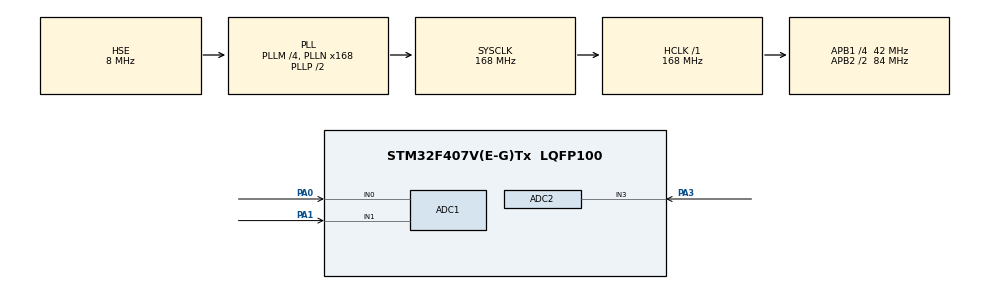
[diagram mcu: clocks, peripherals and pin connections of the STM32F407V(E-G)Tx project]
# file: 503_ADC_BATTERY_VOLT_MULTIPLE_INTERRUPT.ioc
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ADC1.Channel-0\#ChannelRegularConversion=ADC_CHANNEL_VREFINT
ADC1.Channel-3\#ChannelRegularConversion=ADC_CHANNEL_0
ADC1.Channel-4\#ChannelRegularConversion=ADC_CHANNEL_1
ADC1.ContinuousConvMode=ENABLE
ADC1.NbrOfConversion=3
ADC1.NbrOfConversionFlag=1
ADC1.Rank-3\#ChannelRegularConversion=2
ADC1.Rank-4\#ChannelRegularConversion=3
ADC1.SamplingTime-0\#ChannelRegularConversion=ADC_SAMPLETIME_480CYCLES
ADC1.SamplingTime-3\#ChannelRegularConversion=ADC_SAMPLETIME_480CYCLES
ADC1.SamplingTime-4\#ChannelRegularConversion=ADC_SAMPLETIME_480CYCLES
ADC1.master=1
ADC2.Channel-2\#ChannelRegularConversion=ADC_CHANNEL_3
ADC2.ContinuousConvMode=ENABLE
ADC2.NbrOfConversionFlag=1
ADC2.Rank-2\#ChannelRegularConversion=1
ADC2.SamplingTime-2\#ChannelRegularConversion=ADC_SAMPLETIME_480CYCLES
Mcu.Family=STM32F4
Mcu.Name=STM32F407V(E-G)Tx
Mcu.Package=LQFP100
NVIC.ADC_IRQn=true\:0\:0\:false\:false\:true\:true\:true\:true
NVIC.PriorityGroup=NVIC_PRIORITYGROUP_4
PA0-WKUP.Signal=ADCx_IN0
PA1.Signal=ADCx_IN1
PA13.Mode=Serial_Wire
PA13.Signal=SYS_JTMS-SWDIO
PA14.Mode=Serial_Wire
PA14.Signal=SYS_JTCK-SWCLK
PA3.Signal=ADCx_IN3
PH0-OSC_IN.Mode=HSE-External-Oscillator
PH0-OSC_IN.Signal=RCC_OSC_IN
PH1-OSC_OUT.Mode=HSE-External-Oscillator
PH1-OSC_OUT.Signal=RCC_OSC_OUT
ProjectManager.HeapSize=0x200
ProjectManager.StackSize=0x400
ProjectManager.TargetToolchain=STM32CubeIDE
RCC.48MHZClocksFreq_Value=84000000
RCC.AHBFreq_Value=168000000
RCC.APB1CLKDivider=RCC_HCLK_DIV4
RCC.APB1Freq_Value=42000000
RCC.APB1TimFreq_Value=84000000
RCC.APB2CLKDivider=RCC_HCLK_DIV2
RCC.APB2Freq_Value=84000000
RCC.APB2TimFreq_Value=168000000
RCC.CortexFreq_Value=168000000
RCC.HCLKFreq_Value=168000000
RCC.HSE_VALUE=8000000
RCC.HSI_VALUE=16000000
RCC.LSE_VALUE=32768
RCC.PLLM=4
RCC.PLLN=168
RCC.PLLSourceVirtual=RCC_PLLSOURCE_HSE
RCC.SYSCLKFreq_VALUE=168000000
RCC.SYSCLKSource=RCC_SYSCLKSOURCE_PLLCLK
RCC.VCOOutputFreq_Value=336000000
SH.ADCx_IN0.0=ADC1_IN0,IN0
SH.ADCx_IN1.0=ADC1_IN1,IN1
SH.ADCx_IN3.0=ADC2_IN3,IN3
VP_ADC1_Vref_Input.Mode=IN-Vrefint
board=custom

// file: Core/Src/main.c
/* USER CODE BEGIN Header */
/**
  ******************************************************************************
  * @file           : main.c
  * @brief          : Main program body
  ******************************************************************************
  * @attention
  *
  * Copyright (c) 2024 STMicroelectronics.
  * All rights reserved.
  *
  * This software is licensed under terms that can be found in the LICENSE file
  * in the root directory of this software component.
  * If no LICENSE file comes with this software, it is provided AS-IS.
  *
  ******************************************************************************
  */
/* USER CODE END Header */
#include "main.h"

/* USER CODE BEGIN PTD */
#define VREFIN_CAL ((uint16_t*)((uint32_t)0x1FFF7A2A))
uint16_t adc1_value [3];
uint16_t adc2_value;

float Vdda = 0, Vadc1_bat1, Vadc1_bat2, Vadc2_bat1;

int count;

/* USER CODE END PTD */

ADC_HandleTypeDef hadc1;
ADC_HandleTypeDef hadc2;

void SystemClock_Config(void);
static void MX_GPIO_Init(void);
static void MX_ADC1_Init(void);
static void MX_ADC2_Init(void);

/* USER CODE BEGIN 0 */
void HAL_ADC_ConvCpltCallback(ADC_HandleTypeDef *hadc)
{
	if(__HAL_ADC_GET_FLAG(&hadc1, ADC_FLAG_EOC) != RESET )
	{
		adc1_value[count] = HAL_ADC_GetValue(&hadc1);
        count++;

        if(count == 3)
        {
        	count = 0;
        }
        Vdda = (float) 3.3 * (*VREFIN_CAL)/adc1_value[0];

        Vadc1_bat1 = Vdda*adc1_value[1]/4095;
        Vadc1_bat2 = Vdda*adc1_value[2]/4095;

	}

	if(__HAL_ADC_GET_FLAG(&hadc2, ADC_FLAG_EOC) != RESET )
	{
		adc2_value = HAL_ADC_GetValue(&hadc2);

		Vadc2_bat1 = Vdda*adc2_value/4095;
	}

}
/* USER CODE END 0 */

int main(void)
{

  /* MCU Configuration--------------------------------------------------------*/

  /* Reset of all peripherals, Initializes the Flash interface and the Systick. */
  HAL_Init();

  /* Configure the system clock */
  SystemClock_Config();

  /* Initialize all configured peripherals */
  MX_GPIO_Init();
  MX_ADC1_Init();
  MX_ADC2_Init();
  /* USER CODE BEGIN 2 */
HAL_ADC_Start_IT(&hadc1);
HAL_ADC_Start_IT(&hadc2);
  /* USER CODE END 2 */

  /* Infinite loop */
  while (1)
  {

  }
}

void SystemClock_Config(void)
{
  RCC_OscInitTypeDef RCC_OscInitStruct = {0};
  RCC_ClkInitTypeDef RCC_ClkInitStruct = {0};

  /** Configure the main internal regulator output voltage
  */
  __HAL_RCC_PWR_CLK_ENABLE();
  __HAL_PWR_VOLTAGESCALING_CONFIG(PWR_REGULATOR_VOLTAGE_SCALE1);

  /** Initializes the RCC Oscillators according to the specified parameters
  * in the RCC_OscInitTypeDef structure.
  */
  RCC_OscInitStruct.OscillatorType = RCC_OSCILLATORTYPE_HSE;
  RCC_OscInitStruct.HSEState = RCC_HSE_ON;
  RCC_OscInitStruct.PLL.PLLState = RCC_PLL_ON;
  RCC_OscInitStruct.PLL.PLLSource = RCC_PLLSOURCE_HSE;
  RCC_OscInitStruct.PLL.PLLM = 4;
  RCC_OscInitStruct.PLL.PLLN = 168;
  RCC_OscInitStruct.PLL.PLLP = RCC_PLLP_DIV2;
  RCC_OscInitStruct.PLL.PLLQ = 4;
  if (HAL_RCC_OscConfig(&RCC_OscInitStruct) != HAL_OK)
  {
    Error_Handler();
  }

  /** Initializes the CPU, AHB and APB buses clocks
  */
  RCC_ClkInitStruct.ClockType = RCC_CLOCKTYPE_HCLK|RCC_CLOCKTYPE_SYSCLK
                              |RCC_CLOCKTYPE_PCLK1|RCC_CLOCKTYPE_PCLK2;
  RCC_ClkInitStruct.SYSCLKSource = RCC_SYSCLKSOURCE_PLLCLK;
  RCC_ClkInitStruct.AHBCLKDivider = RCC_SYSCLK_DIV1;
  RCC_ClkInitStruct.APB1CLKDivider = RCC_HCLK_DIV4;
  RCC_ClkInitStruct.APB2CLKDivider = RCC_HCLK_DIV2;

  if (HAL_RCC_ClockConfig(&RCC_ClkInitStruct, FLASH_LATENCY_5) != HAL_OK)
  {
    Error_Handler();
  }
}

static void MX_ADC1_Init(void)
{

  ADC_ChannelConfTypeDef sConfig = {0};

  /** Configure the global features of the ADC (Clock, Resolution, Data Alignment and number of conversion)
  */
  hadc1.Instance = ADC1;
  hadc1.Init.ClockPrescaler = ADC_CLOCK_SYNC_PCLK_DIV4;
  hadc1.Init.Resolution = ADC_RESOLUTION_12B;
  hadc1.Init.ScanConvMode = ENABLE;
  hadc1.Init.ContinuousConvMode = ENABLE;
  hadc1.Init.DiscontinuousConvMode = DISABLE;
  hadc1.Init.ExternalTrigConvEdge = ADC_EXTERNALTRIGCONVEDGE_NONE;
  hadc1.Init.ExternalTrigConv = ADC_SOFTWARE_START;
  hadc1.Init.DataAlign = ADC_DATAALIGN_RIGHT;
  hadc1.Init.NbrOfConversion = 3;
  hadc1.Init.DMAContinuousRequests = DISABLE;
  hadc1.Init.EOCSelection = ADC_EOC_SINGLE_CONV;
  if (HAL_ADC_Init(&hadc1) != HAL_OK)
  {
    Error_Handler();
  }

  /** Configure for the selected ADC regular channel its corresponding rank in the sequencer and its sample time.
  */
  sConfig.Channel = ADC_CHANNEL_VREFINT;
  sConfig.Rank = 1;
  sConfig.SamplingTime = ADC_SAMPLETIME_480CYCLES;
  if (HAL_ADC_ConfigChannel(&hadc1, &sConfig) != HAL_OK)
  {
    Error_Handler();
  }

  /** Configure for the selected ADC regular channel its corresponding rank in the sequencer and its sample time.
  */
  sConfig.Channel = ADC_CHANNEL_0;
  sConfig.Rank = 2;
  if (HAL_ADC_ConfigChannel(&hadc1, &sConfig) != HAL_OK)
  {
    Error_Handler();
  }

  /** Configure for the selected ADC regular channel its corresponding rank in the sequencer and its sample time.
  */
  sConfig.Channel = ADC_CHANNEL_1;
  sConfig.Rank = 3;
  if (HAL_ADC_ConfigChannel(&hadc1, &sConfig) != HAL_OK)
  {
    Error_Handler();
  }

}

static void MX_ADC2_Init(void)
{

  ADC_ChannelConfTypeDef sConfig = {0};

  /** Configure the global features of the ADC (Clock, Resolution, Data Alignment and number of conversion)
  */
  hadc2.Instance = ADC2;
  hadc2.Init.ClockPrescaler = ADC_CLOCK_SYNC_PCLK_DIV4;
  hadc2.Init.Resolution = ADC_RESOLUTION_12B;
  hadc2.Init.ScanConvMode = DISABLE;
  hadc2.Init.ContinuousConvMode = ENABLE;
  hadc2.Init.DiscontinuousConvMode = DISABLE;
  hadc2.Init.ExternalTrigConvEdge = ADC_EXTERNALTRIGCONVEDGE_NONE;
  hadc2.Init.ExternalTrigConv = ADC_SOFTWARE_START;
  hadc2.Init.DataAlign = ADC_DATAALIGN_RIGHT;
  hadc2.Init.NbrOfConversion = 1;
  hadc2.Init.DMAContinuousRequests = DISABLE;
  hadc2.Init.EOCSelection = ADC_EOC_SINGLE_CONV;
  if (HAL_ADC_Init(&hadc2) != HAL_OK)
  {
    Error_Handler();
  }

  /** Configure for the selected ADC regular channel its corresponding rank in the sequencer and its sample time.
  */
  sConfig.Channel = ADC_CHANNEL_3;
  sConfig.Rank = 1;
  sConfig.SamplingTime = ADC_SAMPLETIME_480CYCLES;
  if (HAL_ADC_ConfigChannel(&hadc2, &sConfig) != HAL_OK)
  {
    Error_Handler();
  }

}

static void MX_GPIO_Init(void)
{

  /* GPIO Ports Clock Enable */
  __HAL_RCC_GPIOH_CLK_ENABLE();
  __HAL_RCC_GPIOA_CLK_ENABLE();

}

void Error_Handler(void)
{
  __disable_irq();
  while (1)
  {
  }
}
